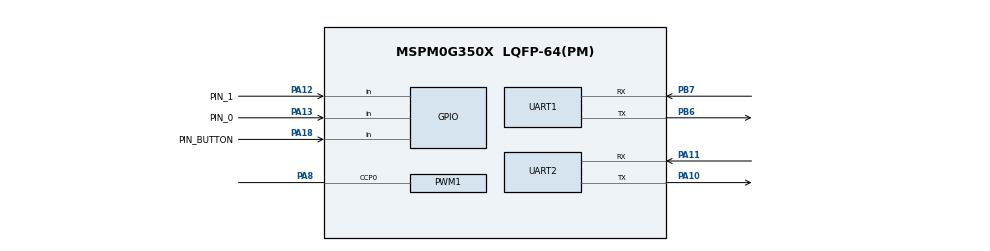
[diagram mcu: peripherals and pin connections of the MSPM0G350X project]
/**
 * @cliArgs --device "MSPM0G350X" --part "Default" --package "LQFP-64(PM)" --product "mspm0_sdk@2.11.00.07"
 * @versions {"tool":"1.26.2+4477"}
 */

/**
 * Import the modules used in this configuration.
 */
const GPIO    = scripting.addModule("/ti/driverlib/GPIO", {}, false);
const GPIO1   = GPIO.addInstance();
const GPIO2   = GPIO.addInstance();
const PWM     = scripting.addModule("/ti/driverlib/PWM", {}, false);
const PWM1    = PWM.addInstance();
const SYSCTL  = scripting.addModule("/ti/driverlib/SYSCTL");
const SYSTICK = scripting.addModule("/ti/driverlib/SYSTICK");
const UART    = scripting.addModule("/ti/driverlib/UART", {}, false);
const UART1   = UART.addInstance();
const UART2   = UART.addInstance();

/**
 * Write custom configuration values to the imported modules.
 */
GPIO1.$name                              = "GPIO_KEY";
GPIO1.associatedPins.create(3);
GPIO1.associatedPins[0].direction        = "INPUT";
GPIO1.associatedPins[0].$name            = "PIN_BUTTON";
GPIO1.associatedPins[0].internalResistor = "PULL_DOWN";
GPIO1.associatedPins[0].assignedPin      = "18";
GPIO1.associatedPins[0].assignedPort     = "PORTA";
GPIO1.associatedPins[0].pin.$assign      = "PA18";
GPIO1.associatedPins[1].$name            = "PIN_0";
GPIO1.associatedPins[1].direction        = "INPUT";
GPIO1.associatedPins[1].internalResistor = "PULL_UP";
GPIO1.associatedPins[1].pin.$assign      = "PA13";
GPIO1.associatedPins[2].$name            = "PIN_1";
GPIO1.associatedPins[2].direction        = "INPUT";
GPIO1.associatedPins[2].internalResistor = "PULL_UP";
GPIO1.associatedPins[2].pin.$assign      = "PA12";

const Board = scripting.addModule("/ti/driverlib/Board", {}, false);

GPIO2.$name                          = "GPIO_LED";
GPIO2.associatedPins[0].$name        = "PIN_2";
GPIO2.associatedPins[0].assignedPort = "PORTA";
GPIO2.associatedPins[0].assignedPin  = "0";

PWM1.$name                              = "SERVO";
PWM1.clockPrescale                      = 16;
PWM1.timerCount                         = 40000;
PWM1.timerStartTimer                    = true;
PWM1.ccIndex                            = [0];
PWM1.pwmMode                            = "EDGE_ALIGN_UP";
PWM1.PWM_CHANNEL_0.$name                = "ti_driverlib_pwm_PWMTimerCC0";
PWM1.PWM_CHANNEL_0.ccValue              = 3000;
PWM1.ccp0PinConfig.direction            = scripting.forceWrite("OUTPUT");
PWM1.ccp0PinConfig.hideOutputInversion  = scripting.forceWrite(false);
PWM1.ccp0PinConfig.onlyInternalResistor = scripting.forceWrite(false);
PWM1.ccp0PinConfig.passedPeripheralType = scripting.forceWrite("Digital");
PWM1.ccp0PinConfig.$name                = "ti_driverlib_gpio_GPIOPinGeneric0";
PWM1.peripheral.$assign                 = "TIMA0";
PWM1.peripheral.ccp0Pin.$assign         = "PA8";

SYSCTL.forceDefaultClkConfig = true;

SYSTICK.periodEnable  = true;
SYSTICK.period        = 32;
SYSTICK.systickEnable = true;

UART1.$name                            = "UART_K230";
UART1.targetBaudRate                   = 115200;
UART1.peripheral.$assign               = "UART1";
UART1.peripheral.rxPin.$assign         = "PB7";
UART1.peripheral.txPin.$assign         = "PB6";
UART1.txPinConfig.direction            = scripting.forceWrite("OUTPUT");
UART1.txPinConfig.hideOutputInversion  = scripting.forceWrite(false);
UART1.txPinConfig.onlyInternalResistor = scripting.forceWrite(false);
UART1.txPinConfig.passedPeripheralType = scripting.forceWrite("Digital");
UART1.txPinConfig.$name                = "ti_driverlib_gpio_GPIOPinGeneric1";
UART1.rxPinConfig.hideOutputInversion  = scripting.forceWrite(false);
UART1.rxPinConfig.onlyInternalResistor = scripting.forceWrite(false);
UART1.rxPinConfig.passedPeripheralType = scripting.forceWrite("Digital");
UART1.rxPinConfig.$name                = "ti_driverlib_gpio_GPIOPinGeneric2";

UART2.targetBaudRate                   = 115200;
UART2.$name                            = "UART_0";
UART2.peripheral.$assign               = "UART0";
UART2.peripheral.rxPin.$assign         = "PA11";
UART2.peripheral.txPin.$assign         = "PA10";
UART2.txPinConfig.direction            = scripting.forceWrite("OUTPUT");
UART2.txPinConfig.hideOutputInversion  = scripting.forceWrite(false);
UART2.txPinConfig.onlyInternalResistor = scripting.forceWrite(false);
UART2.txPinConfig.passedPeripheralType = scripting.forceWrite("Digital");
UART2.txPinConfig.$name                = "ti_driverlib_gpio_GPIOPinGeneric3";
UART2.rxPinConfig.hideOutputInversion  = scripting.forceWrite(false);
UART2.rxPinConfig.onlyInternalResistor = scripting.forceWrite(false);
UART2.rxPinConfig.passedPeripheralType = scripting.forceWrite("Digital");
UART2.rxPinConfig.$name                = "ti_driverlib_gpio_GPIOPinGeneric4";

/**
 * Pinmux solution for unlocked pins/peripherals. This ensures that minor changes to the automatic solver in a future
 * version of the tool will not impact the pinmux you originally saw.  These lines can be completely deleted in order to
 * re-solve from scratch.
 */
Board.peripheral.$suggestSolution            = "DEBUGSS";
Board.peripheral.swclkPin.$suggestSolution   = "PA20";
Board.peripheral.swdioPin.$suggestSolution   = "PA19";
GPIO2.associatedPins[0].pin.$suggestSolution = "PA0";
SYSCTL.peripheral.$suggestSolution           = "SYSCTL";
